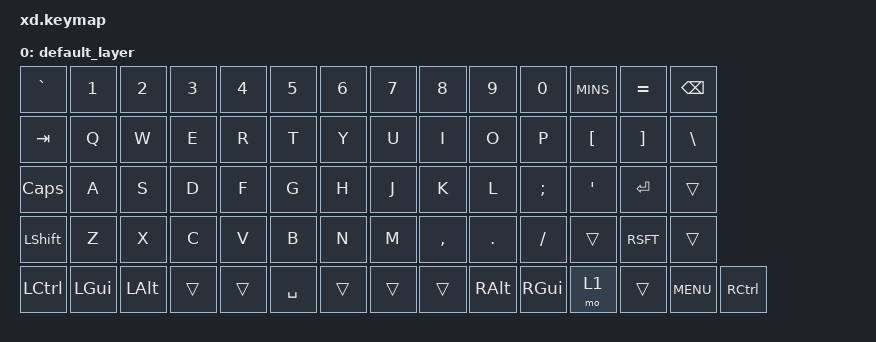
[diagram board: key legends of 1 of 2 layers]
// This file was generated from a template. Edit it to match your keyboard.
// See https://zmk.dev/docs/development/hardware-integration/new-shield for more instructions.

#include <behaviors.dtsi>
#include <dt-bindings/zmk/keys.h>
#include <dt-bindings/zmk/bt.h>
#include <dt-bindings/zmk/outputs.h>

/ {
    keymap {
        compatible = "zmk,keymap";
        default_layer {
            bindings = <
                &kp GRAVE  &kp N1     &kp N2     &kp N3     &kp N4     &kp N5     &kp N6     &kp N7     &kp N8     &kp N9     &kp N0     &kp MINS   &kp EQL    &kp BSPC
                &kp TAB    &kp Q      &kp W      &kp E      &kp R      &kp T      &kp Y      &kp U      &kp I      &kp O      &kp P      &kp LBKT   &kp RBKT   &kp BSLH
                &kp CLCK   &kp A      &kp S      &kp D      &kp F      &kp G      &kp H      &kp J      &kp K      &kp L      &kp SCLN   &kp QUOT   &kp RET    &trans
                &kp LSHFT  &kp Z      &kp X      &kp C      &kp V      &kp B      &kp N      &kp M      &kp COMMA  &kp DOT    &kp FSLH   &trans     &kp RSFT   &trans
                &kp LCTRL  &kp LGUI   &kp LALT   &trans     &trans     &kp SPACE  &trans     &trans     &trans     &kp RALT   &kp RGUI &mo 1   &trans     &kp MENU   &kp RCTRL
            >;
        };
        raise_layer {
            bindings = <
                &bt BT_CLR &bt BT_SEL 0 &bt BT_SEL 1 &bt BT_SEL 2 &bt BT_SEL 3 &bt BT_SEL 4 &bt BT_SEL 5 &trans &trans &trans &trans &out OUT_TOG &bootloader
                &trans &trans &trans &trans &trans &trans &trans &trans &trans &trans &trans &trans &trans &trans
                &trans &trans &trans &trans &trans &trans &trans &trans &trans &trans &trans &trans &trans &trans
                &trans &trans &trans &trans &trans &trans &trans &trans &trans &trans &trans &trans &trans &trans
                &trans &trans &trans &trans &trans &trans &trans &trans &trans &trans &trans &trans &trans &trans
                
            >;
        };
    };
};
